# PIC18LF8310 register map
Vendor: Microchip
Architecture 18xxxx. Special function registers and configuration words.
Registers are 8-bit, read-write, reset 0x0 unless marked. A register's access mark holds for its fields unless they carry their own. Addresses are absolute, and some are shared; only a register's first bit layout is shown; lines under a group give offsets from that group; [hi:lo] are bit positions; {n}, {i} and the like mark numbered series; 'fields as' and 'values as' point back to an identical list; <NAME> marks a mode.

## Further device data
pins=1: RH2/AD18; 2: RH3/AD19; 3: RE1/AD9/WR; 4: RE0/AD8/RD; 5: RG0/CCP3; 6: RG1/TX2/CK2; 7: RG2/RX2/DT2; 8: RG3; 9: RG5/MCLR/Vpp; 10: RG4; 11: Vss; 12: Vdd; 13: RF7/SS; 14: RF6/AN11; 15: RF5/AN10/CVref; 16: RF4/AN9; 17: RF3/AN8; 18: RF2/AN7/C1OUT; 19: RH7; 20: RH6; 21: RH5; 22: RH4; 23: RF1/AN6/C2OUT; 24: RF0/AN5; 25: AVdd; 26: AVss; 27: RA3/AN3/Vref+; 28: RA2/AN2/Vref-; 29: RA1/AN1; 30: RA0/AN0; 31: Vss; 32: Vdd; 33: RA5/AN4/HLVDIN; 34: RA4/T0CKI; 35: RC1/T1OSI/CCP2; 36: RC0/T1OSO/T13CKI; 37: RC6/TX1/CK1; 38: RC7/RX1/DT1; 39: RJ4/BA0; 40: RJ5/CE; 41: RJ6/LB; 42: RJ7/UB; 43: RC2/CCP1; 44: RC3/SCK/SCL; 45: RC4/SDI/SDA; 46: RC5/SDO; 47: RB7/KBI3/PGD; 48: Vdd; 49: OSC1/CLKI/RA7; 50: OSC2/CLKO/RA6; 51: Vss; 52: RB6/KBI2/PGC; 53: RB5/KBI1; 54: RB4/KBI0; 55: RB3/INT3/CCP2; 56: RB2/INT2; 57: RB1/INT1; 58: RB0/INT0; 59: RJ3/WRH; 60: RJ2/WRL; 61: RJ1/OE; 62: RJ0/ALE; 63: RD7/AD7/PSP7; 64: RD6/AD6/PSP6; 65: RD5/AD5/PSP5; 66: RD4/AD4/PSP4; 67: RD3/AD3/PSP3; 68: RD2/AD2/PSP2; 69: RD1/AD1/PSP1; 70: Vss; 71: Vdd; 72: RD0/AD0/PSP0; 73: RE7/CCP2/AD15; 74: RE6/AD14; 75: RE5/AD13; 76: RE4/AD12; 77: RE3/AD11; 78: RE2/AD10/CS; 79: RH0/AD16; 80: RH1/AD17

## CONFIG — Configuration words, addresses in ProgramSpace
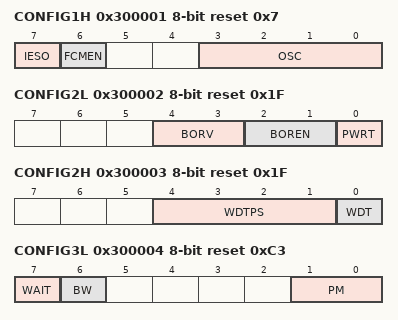
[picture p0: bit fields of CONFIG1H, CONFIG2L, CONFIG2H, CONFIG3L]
0x300001 CONFIG1H reset 0x7
  [7] IESO — Internal External Switch Over Mode
    0=OFF (Oscillator Switchover mode disabled); 1=ON (Oscillator Switchover mode enabled)
  [6] FCMEN — Fail-Safe Clock Monitor Enable
    0=OFF (Fail-Safe Clock Monitor disabled); 1=ON (Fail-Safe Clock Monitor enabled)
  [3:0] OSC — Oscillator
    0b11xx=11XX EXT RC-CLKOUT on RA6; 0b101x=101X EXT RC-CLKOUT on RA6; 9=INTIO7 (Internal oscillator block, CLKO function on RA6, port function on RA7); 8=INTIO67 (Internal oscillator block, port function on RA6 and RA7); 7=RCIO (External RC oscillator, port function on RA6); 6=HSPLL (HS oscillator, PLL enabled (clock frequency = 4 x FOSC1)); 5=ECIO (EC oscillator, port function on RA6); 4=EC (EC oscillator, CLKO function on RA6); 3=RC (External RC oscillator, CLKO function on RA6); 2=HS (HS oscillator); 1=XT (XT oscillator); 0=LP (LP oscillator)
0x300002 CONFIG2L reset 0x1F
  [4:3] BORV — Brown Out Voltage
    3=VBOR set to 2.1V; 2=VBOR set to 2.8V; 1=VBOR set to 4.3V; 0=VBOR set to 4.6V
  [2:1] BOREN — Brown Out Detect
    3=SBORDIS (Brown-out Reset enabled in hardware only (SBOREN is disabled)); 2=NOSLP (Brown-out Reset enabled in hardware only and disabled in Sleep mode (SBOREN is disabled)); 1=ON (Brown-out Reset enabled and controlled by software (SBOREN is enabled)); 0=OFF (Brown-out Reset disabled in hardware and software)
  [0] PWRT — Power Up Timer
    1=OFF (PWRT disabled); 0=ON (PWRT enabled)
0x300003 CONFIG2H reset 0x1F
  [4:1] WDTPS — Watchdog Postscaler
    15=1:32768; 14=1:16384; 13=1:8192; 12=1:4096; 11=1:2048; 10=1:1024; 9=1:512; 8=1:256; 7=1:128; 6=1:64; 5=1:32; 4=1:16; 3=1:8; 2=1:4; 1=1:2; 0=1:1
  [0] WDT — Watchdog Timer
    1=ON (WDT enabled); 0=OFF (WDT disabled (control is placed on the SWDTEN bit))
0x300004 CONFIG3L reset 0xC3
  [7] WAIT — External Bus Wait
    1=OFF (Wait selections unavailable, device will not wait); 0=ON (Wait programmed by WAIT1 and WAIT0 bits of MEMCOM register (MEMCOM<5:4>))
  [6] BW — Bus Width
    1=16-bit External Bus Data Width; 0=8-bit External Bus Data Width
  [1:0] PM — Processor Mode
    3=MC (Microcontroller mode); 2=MP (Microprocessor mode); 1=MPB (Microprocessor with Boot Block mode); 0=EM (Extended Microcontroller mode)
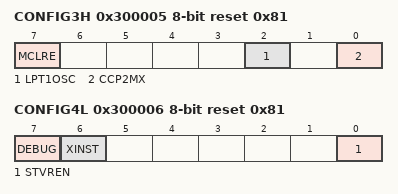
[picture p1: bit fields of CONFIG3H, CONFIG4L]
0x300005 CONFIG3H reset 0x81
  [7] MCLRE — Master Clear Enable
    1=ON (MCLR pin enabled; RG5 input pin disabled); 0=OFF (RG5 input pin enabled; MCLR disabled)
  [2] LPT1OSC — Low Power Timer1 Osc enable
    1=ON (Timer1 configured for low-power operation); 0=OFF (Timer1 configured for higher power operation)
  [0] CCP2MX — CCP2 Mux
    1=PORTC (CCP2 input/output is multiplexed with RC1); 0=PORTBE (CCP2 is multiplexed with RB3 in Extended Microcontroller, Microprocessor or Microprocessor with Boot Block mode. Or with RE7 in Microcontroller mode.)
0x300006 CONFIG4L reset 0x81
  [7] DEBUG — Background Debugger Enable bit
    1=OFF (Background debugger disabled, RB6 and RB7 configured as general purpose I/O pins); 0=ON (Background debugger enabled, RB6 and RB7 are dedicated to In-Circuit Debug)
  [6] XINST — Extended Instruction Set Enable bit
    1=ON (Instruction set extension and Indexed Addressing mode enabled); 0=OFF (Instruction set extension and Indexed Addressing mode disabled (Legacy mode))
  [0] STVREN — Stack Overflow Reset
    1=ON (Stack full/underflow will cause Reset); 0=OFF (Stack full/underflow will not cause Reset)
0x300008 CONFIG5L reset 0x1
  [0] CP — Code Protect 00000-01FFF
    1=OFF (Program memory block not code-protected); 0=ON (Program memory block code-protected)
0x30000C CONFIG7L reset 0x1
  [0] EBTR — Table Read Protect 00000-01FFF
    1=OFF (Internal program memory block not protected from table reads executed from external memory block); 0=ON (Internal program memory block protected from table reads executed from external memory block)
